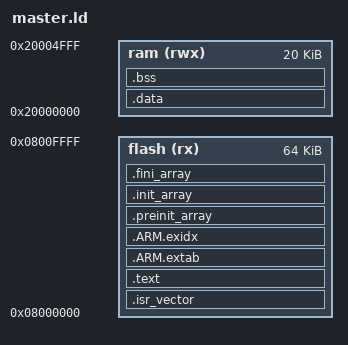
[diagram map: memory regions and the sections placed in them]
/*
 * GCC linker script for STM32 microcontrollers (ARM Cortex-M).
 *
 * It exports the symbols needed for the CMSIS assembler startup script for GCC
 * ARM toolchains (_sidata, _sdata, _edata, _sbss, _ebss) and sets the entry
 * point to Reset_Handler.
 *
 * Adapt FLASH/RAM size for your particular device below.
 *
 * @author Bjørn Forsman
 * @author Oleg Borodin
 */

MEMORY
{
    flash (rx) : ORIGIN = 0x08000000, LENGTH = 64K
    ram  (rwx) : ORIGIN = 0x20000000, LENGTH = 20K
}

ENTRY(Reset_Handler);

SECTIONS
{
    /* Reset and ISR vectors */
    .isr_vector : {
        __isr_vector_start__ = .;
        KEEP(*(.isr_vector)) /* without 'KEEP' the garbage collector discards this section */
        ASSERT(. != __isr_vector_start__, "The .isr_vector section is empty");
    } >flash


    /* Text section (code and read-only data) */
    .text : {
        . = ALIGN(4);
        _stext = .;
        *(.text*)   /* code */
        *(.rodata*) /* read only data */

        /*
         * NOTE: .glue_7 and .glue_7t sections are not needed because Cortex-M
         * only supports Thumb instructions, no ARM/Thumb interworking.
         */

        /* Static constructors and destructors */
        KEEP(*(.init))
        KEEP(*(.fini))

        . = ALIGN(4);
        _etext = .;
    } >flash


    /*
     * Stack unwinding and exception handling sections.
     *
     * ARM compilers emit object files with .ARM.extab and .ARM.exidx sections
     * when using C++ exceptions. Also, at least GCC emits those sections when
     * dividing large numbers (64-bit) in C. So we have to handle them.
     *
     * (ARM uses .ARM.extab and .ARM.exidx instead of the .eh_frame section
     * used on x86.)
     */
    /* Exception unwinding information */
    .ARM.extab : {
        *(.ARM.extab*)
    } >flash

    /* Index entries for section unwinding */
    .ARM.exidx : {
        *(.ARM.exidx*)
    } >flash


    /*
     * Newlib and Eglibc (at least) need these for C++ support.
     *
     * (Copied from Sourcery CodeBench Lite: arm-none-eabi-gcc -V)
     */
    .preinit_array : {
        PROVIDE_HIDDEN(__preinit_array_start = .);
        KEEP(*(.preinit_array*))
        PROVIDE_HIDDEN(__preinit_array_end = .);
    } >flash

    .init_array : {
        PROVIDE_HIDDEN(__init_array_start = .);
        KEEP(*(SORT(.init_array.*)))
        KEEP(*(.init_array*))
        PROVIDE_HIDDEN(__init_array_end = .);
    } >flash

    .fini_array : {
        PROVIDE_HIDDEN(__fini_array_start = .);
        KEEP(*(SORT(.fini_array.*)))
        KEEP(*(.fini_array*))
        PROVIDE_HIDDEN(__fini_array_end = .);
    } >flash


    /*
     * Initialized data section. This section is programmed into FLASH (LMA
     * address) and copied to RAM (VMA address) in startup code.
     */
    _sidata = .;
    _data = .;
    .data : AT(_sidata) {

        . = ALIGN(4);
        _sdata = .; 
        *(.data*)
        . = ALIGN(4);
        _edata = .;
    } >ram
    _data_loadaddr = LOADADDR(.data);


    /* Uninitialized data section (zeroed out by startup code) */
    .bss : {
        . = ALIGN(4);
        _sbss = .;
        *(.bss*)
        *(COMMON)
        . = ALIGN(4);
        _ebss = .;
    } >ram

    _end = .;

}

PROVIDE(_heap = _end );
PROVIDE(_stack = ORIGIN(ram) + LENGTH(ram));
PROVIDE(_estack = ORIGIN(ram) + LENGTH(ram));

/* EOF */
